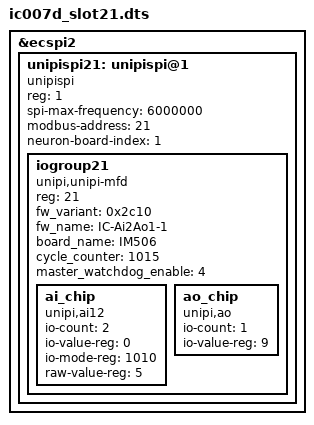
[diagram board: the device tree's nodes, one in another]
/dts-v1/;


/plugin/;

/ {
	fragment@1 {
		
		target = <&ecspi2>;
		__overlay__ {
			status = "okay";
			#address-cells = <1>;
			#size-cells = <0>;

			unipispi21: unipispi@1 {
				compatible = "unipispi";
				reg = <1>;
				status = "okay";
				spi-max-frequency = <6000000>;
				modbus-address = <21>;
				neuron-board-index = <1>;
			};
		};

	};

	fragment@2 {
		target = <&unipispi21>;
		__overlay__ {
			#address-cells = <1>;
			#size-cells = <0>;

			iogroup21 {
				reg = <21>;
				compatible = "unipi,unipi-mfd", "iogroup";
				fw_variant = <0x2c10>;
				fw_name = "IC-Ai2Ao1-1";
				board_name = "IM506";
				cycle_counter = <1015>;
				master_watchdog_enable = <4>;

				ai_chip {
					compatible = "unipi,ai12";
					io-count = <2>;
					io-value-reg = <0>;
					io-mode-reg = <1010>;
					raw-value-reg = <5>;
				};
				ao_chip {
                    compatible = "unipi,ao";
                    io-count = <1>;
                    io-value-reg = <9>;
                };

			};
		};
	};
};
